# STM32WL3R register map
File version: 1.0
CPU: CM0+ r0p0, little endian, MPU, no FPU, 4 interrupt priority bits
Registers are 32-bit, read-write, reset 0x0 unless marked. A register's access mark holds for its fields unless they carry their own. Offsets are from the block's base; [hi:lo] are bit positions.

## IWDG — IWDG address block description
Base 0x40003000
0x00 IWDG_KR
  [15:0] KEY wo — Key value.
0x04 IWDG_PR
  [2:0] PR — Prescaler divider.
0x08 IWDG_RLR reset 0xFFF
  [11:0] RL — Watchdog counter reload value.
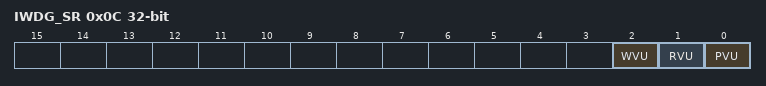
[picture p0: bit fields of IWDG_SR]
0x0C IWDG_SR ro
  [2] WVU — Watchdog counter window value update.
  [1] RVU — Watchdog counter reload value update.
  [0] PVU — Watchdog prescaler value update.
0x10 IWDG_WINR reset 0xFFF
  [11:0] WIN — Watchdog counter window value.

## MISC — MISC_REG_BLOCK address block description
Base 0x49000700
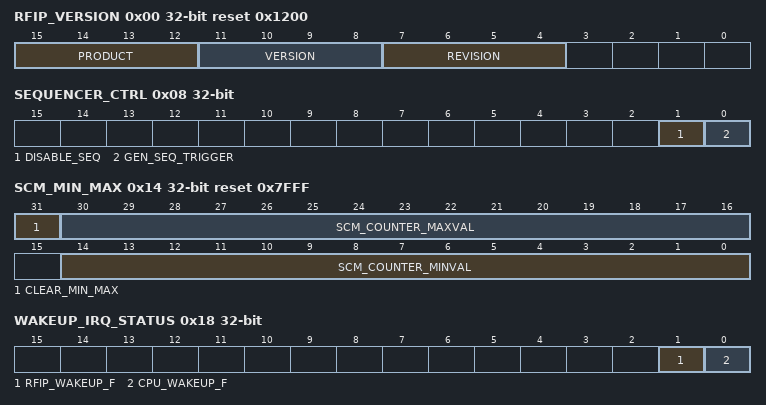
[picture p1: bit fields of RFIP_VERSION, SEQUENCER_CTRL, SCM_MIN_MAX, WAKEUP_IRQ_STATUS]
0x00 RFIP_VERSION ro reset 0x1200
  [15:12] PRODUCT — Used for major upgrades (new protocols support / new features)
  [11:8] VERSION — Version of the MR_SubG (to be used for cut upgrades)
  [7:4] REVISION — Revision of the MR_SubG to be used for metal fixes)
0x04 RRM_UDRA_CTRL
  [0] RRM_CMD_REQ wo — Action bit: write 1 to request a RRM-UDRA command. The RRM checks the RRM_CMDLIST_PTR[31] = CMDLIST_VALID bit and, if set, starts fetching the command in RAM.
0x08 SEQUENCER_CTRL
  [1] DISABLE_SEQ — Set this bit to disable an on-going sequence and mask trigger events.
  [0] GEN_SEQ_TRIGGER wo — Action bit, write 1 to generate a trigger event on Sequencer.
0x0C ABSOLUTE_TIME ro
  [31:0] ABSOLUTE_TIME — Indicate an abolute time with 4 LSB interpolated.
0x10 SCM_COUNTER_VAL ro
  [14:0] SCM_COUNTER_CURRVAL — Slow Clock Measurement: number of 16 MHz clock cycles contained in 32 slow clock periods.
0x14 SCM_MIN_MAX reset 0x7FFF
  [31] CLEAR_MIN_MAX wo — Write 1' to clear the SLOWCLK_MIN_VALUE and SLOWCLK_MAX_VALUE registers.
  [30:16] SCM_COUNTER_MAXVAL ro — Slow Clock Measurement: maximum SCM_COUNTER value seen since the counter is ON and since last clear request.
  [14:0] SCM_COUNTER_MINVAL ro — Slow Clock Measurement: minimum SCM_COUNTER value seen since the counter is ON and since last clear request.
0x18 WAKEUP_IRQ_STATUS
  [1] RFIP_WAKEUP_F — Set when the absolute time matches the RFIP_WAKEUPTIME while WAKEUP_CTRL.RFIP_WAKEUP_EN=1.
  [0] CPU_WAKEUP_F — Set when the absolute time matches the CPU_WAKEUPTIME while WAKEUP_CTRL.CPU_WAKEUP_EN=1.

## RETAINED — RETAINED_REG_BLOCK address block description
Base 0x49000780
0x00 RFIP_WAKEUPTIME ro
  [31:0] RFIP_WAKEUPTIME — (Absolute) Target time to wakeup the RFIP.
0x04 CPU_WAKEUPTIME
  [31:0] CPU_WAKEUPTIME — (Absolute) Target time to wakeup the CPU.
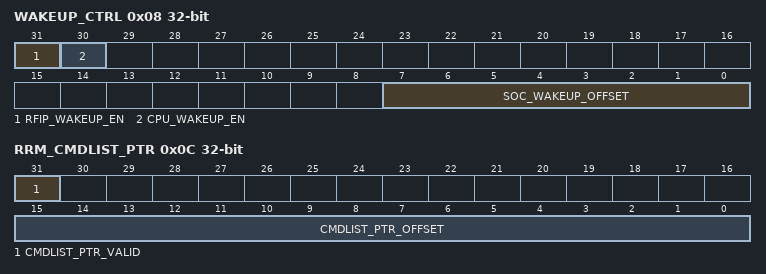
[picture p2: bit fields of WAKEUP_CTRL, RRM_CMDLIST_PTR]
0x08 WAKEUP_CTRL
  [31] RFIP_WAKEUP_EN ro — Indicates if the wakeup timer has to wakeup the SoC + trigger an event on the sequencer + sets the CPU_WAKEUP_F in the WAKEUP_IRQ_STATUS misc register when trigger event occurs.
  [30] CPU_WAKEUP_EN — Indicates if the wakeup timer has to wakeup the SoC + sets the CPU_WAKEUP_F in the WAKEUP_IRQ_STATUS misc register when trigger event occurs
  [7:0] SOC_WAKEUP_OFFSET — Delay to be taken into account by the Wakeup block to anticipate the wakeup req to the PWRC of the SoC versus the target to wakeup the RFIP (or the CPU)
0x0C RRM_CMDLIST_PTR
  [31] CMDLIST_PTR_VALID — Indicate if a command list has to be executed or not:
  [15:0] CMDLIST_PTR_OFFSET — Contain the offset versus the RAM base address of the RRM-UDRA command list entry point.
0x10 SEQ_GLOBALTABLE_PTR
  [15:0] SEQ_GLOBALTABLE_PTR — Contain the offset versus the RAM base address of the GlobalConfiguration RAM table entry point

## RNG — RNG address block description
Base 0x48600000
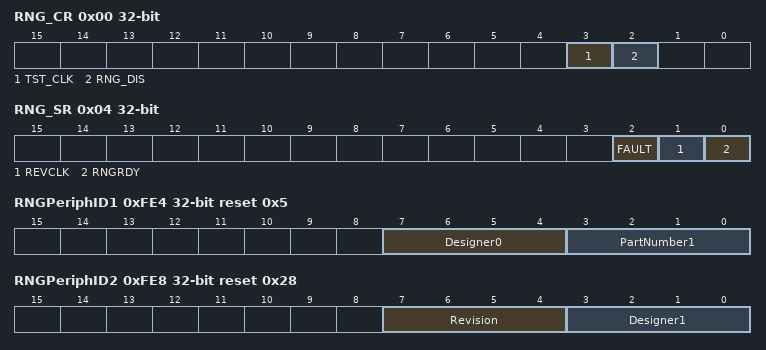
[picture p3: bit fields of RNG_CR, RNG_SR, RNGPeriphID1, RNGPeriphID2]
0x00 RNG_CR
  [3] TST_CLK — RNG Test Clock bit.
  [2] RNG_DIS — RNG Disable bit.
0x04 RNG_SR
  [2] FAULT — Fault Reveal bit.
  [1] REVCLK ro — RNGCLK Clock Reveal bit.
  [0] RNGRDY ro — New Random Value Ready.
0x08 RNG_VAL ro
  [15:0] RANDOM_VALUE
0x80 RNG_TCR
  [0] TCR — Test-control register
0x84 RNG_ITIP
  [0] ITIP — Integration-test input register
0xFE0 RNGPeriphID0 ro reset 0xE1
  [7:0] PartNumber0 — These bits are read back as 0xE1
0xFE4 RNGPeriphID1 ro reset 0x5
  [7:4] Designer0 — These bits are read back as 0x00
  [3:0] PartNumber1 — These bits are read back as 0x05
0xFE8 RNGPeriphID2 ro reset 0x28
  [7:4] Revision — These bits are read back as 0x02
  [3:0] Designer1 — These bits are read back as 0x08
0xFEC RNGPeriphID3 ro
  [7:0] Configuration — These bits are read back as 0x00
0xFF0 RNGPCellID0 ro reset 0xD
  [7:0] RNGPCellID0 — These bits are read back as 0x0D
0xFF4 RNGPCellID1 ro reset 0xF0
  [7:0] RNGPCellID1 — These bits are read back as 0xF0
0xFF8 RNGPCellID2 ro reset 0x5
  [7:0] RNGPCellID2 — These bits are read back as 0x05
0xFFC RNGPCellID3 ro reset 0xB1
  [7:0] RNGPCellID3 — These bits are read back as 0xB1

## SPI3 — SPI3 address block description
Base 0x41002000
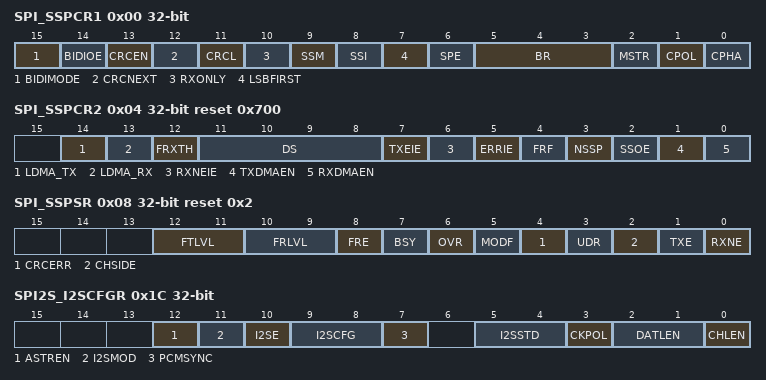
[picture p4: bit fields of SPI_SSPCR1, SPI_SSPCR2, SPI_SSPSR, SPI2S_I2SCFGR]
0x00 SPI_SSPCR1
  [15] BIDIMODE — Bidirectional data mode enable.
  [14] BIDIOE — Output enable in bidirectional mode
  [13] CRCEN — Hardware CRC calculation enable
  [12] CRCNEXT — Transmit CRC next
  [11] CRCL — CRC length
  [10] RXONLY — Receive only mode enabled.
  [9] SSM — Software slave management
  [8] SSI — Internal slave select
  [7] LSBFIRST — Frame format
  [6] SPE — SPI enable
  [5:3] BR — Baud rate control
  [2] MSTR — Master selection
  [1] CPOL — Clock polarity
  [0] CPHA — Clock phase
0x04 SPI_SSPCR2 reset 0x700
  [14] LDMA_TX — Last DMA transfer for transmission
  [13] LDMA_RX — Last DMA transfer for reception
  [12] FRXTH — FIFO reception threshold
  [11:8] DS — Data size
  [7] TXEIE — Tx buffer empty interrupt enable
  [6] RXNEIE — RX buffer not empty interrupt enable
  [5] ERRIE — Error interrupt enable
  [4] FRF — Frame format
  [3] NSSP — NSS pulse management
  [2] SSOE — SS output enable
  [1] TXDMAEN — Tx buffer DMA enable
  [0] RXDMAEN — Rx buffer DMA enable
0x08 SPI_SSPSR reset 0x2
  [12:11] FTLVL ro — FIFO Transmission Level
  [10:9] FRLVL ro — FIFO reception level
  [8] FRE ro — Frame format error
  [7] BSY ro — Busy flag
  [6] OVR ro — Overrun flag
  [5] MODF ro — Mode fault
  [4] CRCERR — CRC error flag
  [3] UDR ro — Underrun flag
  [2] CHSIDE ro — Channel side
  [1] TXE ro — Transmit buffer empty
  [0] RXNE ro — Receive buffer not empty
0x0C SPI_SSPDR
  [15:0] DR — Data register
0x10 SPI_SSPCRCPR reset 0x7
  [15:0] CRCPOLY — CRC polynomial register
0x14 SPI_SSPRXCRCR ro
  [15:0] RXCRC
0x18 SPI_SSPTXCRCR ro
  [0] TXCRC
0x1C SPI2S_I2SCFGR
  [12] ASTREN — Asynchronous start enable.
    0=The Asynchronous start is disabled; 1=The Asynchronous start is enabled
  [11] I2SMOD — I2S mode selection
  [10] I2SE — I2S enable
  [9:8] I2SCFG — I2S configuration mode
  [7] PCMSYNC — PCM frame synchronization
  [5:4] I2SSTD — I2S standard selection
  [3] CKPOL — Steady state clock polarity
  [2:1] DATLEN — Data length to be transferred
  [0] CHLEN — Channel length (number of bits per audio channel)
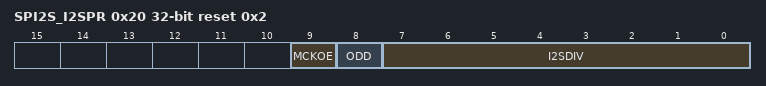
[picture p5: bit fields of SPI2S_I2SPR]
0x20 SPI2S_I2SPR reset 0x2
  [9] MCKOE — Master clock output enable
  [8] ODD — Odd factor for the prescaler
  [7:0] I2SDIV — I2S linear prescaler
